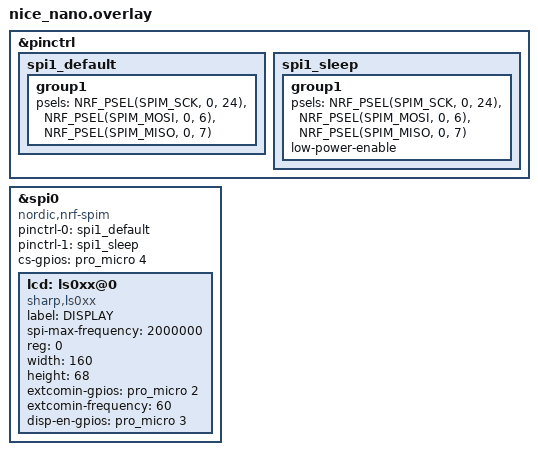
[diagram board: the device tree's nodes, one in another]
/*
 * Copyright (c) 2021 The ZMK Contributors
 *
 * SPDX-License-Identifier: MIT
 */
 &pinctrl {
	spi1_default: spi1_default {
		group1 {
			psels = <NRF_PSEL(SPIM_SCK, 0, 24)>,
					<NRF_PSEL(SPIM_MOSI, 0, 6)>,
					<NRF_PSEL(SPIM_MISO, 0, 7)>;
		};
	};

	spi1_sleep: spi1_sleep {
		group1 {
			psels = <NRF_PSEL(SPIM_SCK, 0, 24)>,
					<NRF_PSEL(SPIM_MOSI, 0, 6)>,
					<NRF_PSEL(SPIM_MISO, 0, 7)>;
			low-power-enable;
		};
	};
};

&spi0 {
    status = "okay";
    compatible = "nordic,nrf-spim";
	pinctrl-0 = <&spi1_default>;
	pinctrl-1 = <&spi1_sleep>;
	pinctrl-names = "default", "sleep";
    cs-gpios = <&pro_micro 4 GPIO_ACTIVE_HIGH>;
    // Unused pin, needed for SPI definition, but not used by the display driver itself.

	lcd: ls0xx@0 {
		compatible = "sharp,ls0xx";
		label = "DISPLAY";
		spi-max-frequency = <2000000>;
		reg = <0>;
		width = <160>;
		height = <68>;
		extcomin-gpios = <&pro_micro 2 GPIO_ACTIVE_HIGH>;
		extcomin-frequency = <60>;
		disp-en-gpios = <&pro_micro 3 GPIO_ACTIVE_HIGH>; 
	};
};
